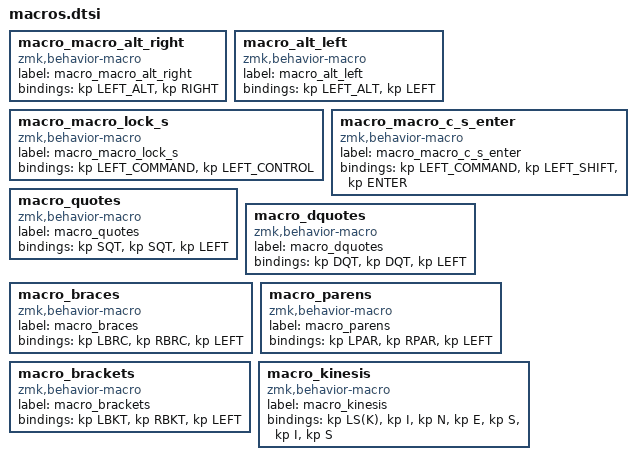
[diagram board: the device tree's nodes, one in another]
macro_macro_alt_right: macro_macro_alt_right{
compatible = "zmk,behavior-macro";
label = "macro_macro_alt_right";
#binding-cells = <0>;
bindings = <&kp LEFT_ALT>, <&kp RIGHT>;
};
macro_alt_left: macro_alt_left{
compatible = "zmk,behavior-macro";
label = "macro_alt_left";
#binding-cells = <0>;
bindings = <&kp LEFT_ALT>, <&kp LEFT>;
};
macro_macro_lock_s: macro_macro_lock_s{
compatible = "zmk,behavior-macro";
label = "macro_macro_lock_s";
#binding-cells = <0>;
bindings = <&kp LEFT_COMMAND>, <&kp LEFT_CONTROL>;
};
macro_macro_c_s_enter: macro_macro_c_s_enter{
compatible = "zmk,behavior-macro";
label = "macro_macro_c_s_enter";
#binding-cells = <0>;
bindings = <&kp LEFT_COMMAND>, <&kp LEFT_SHIFT>, <&kp ENTER>;
};
macro_quotes: macro_quotes{
compatible = "zmk,behavior-macro";
label = "macro_quotes";
#binding-cells = <0>;
bindings = <&kp SQT>, <&kp SQT>, <&kp LEFT>;
};
macro_dquotes: macro_dquotes{
compatible = "zmk,behavior-macro";
label = "macro_dquotes";
#binding-cells = <0>;
bindings = <&kp DQT>, <&kp DQT>, <&kp LEFT>;
};
macro_braces: macro_braces{
compatible = "zmk,behavior-macro";
label = "macro_braces";
#binding-cells = <0>;
bindings = <&kp LBRC>, <&kp RBRC>, <&kp LEFT>;
};
macro_parens: macro_parens{
compatible = "zmk,behavior-macro";
label = "macro_parens";
#binding-cells = <0>;
bindings = <&kp LPAR>, <&kp RPAR>, <&kp LEFT>;
};
macro_brackets: macro_brackets{
compatible = "zmk,behavior-macro";
label = "macro_brackets";
#binding-cells = <0>;
bindings = <&kp LBKT>, <&kp RBKT>, <&kp LEFT>;
};
macro_kinesis: macro_kinesis{
compatible = "zmk,behavior-macro";
label = "macro_kinesis";
#binding-cells = <0>;
bindings = <&kp LS(K)>, <&kp I>, <&kp N>, <&kp E>, <&kp S>, <&kp I>, <&kp S>;
};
